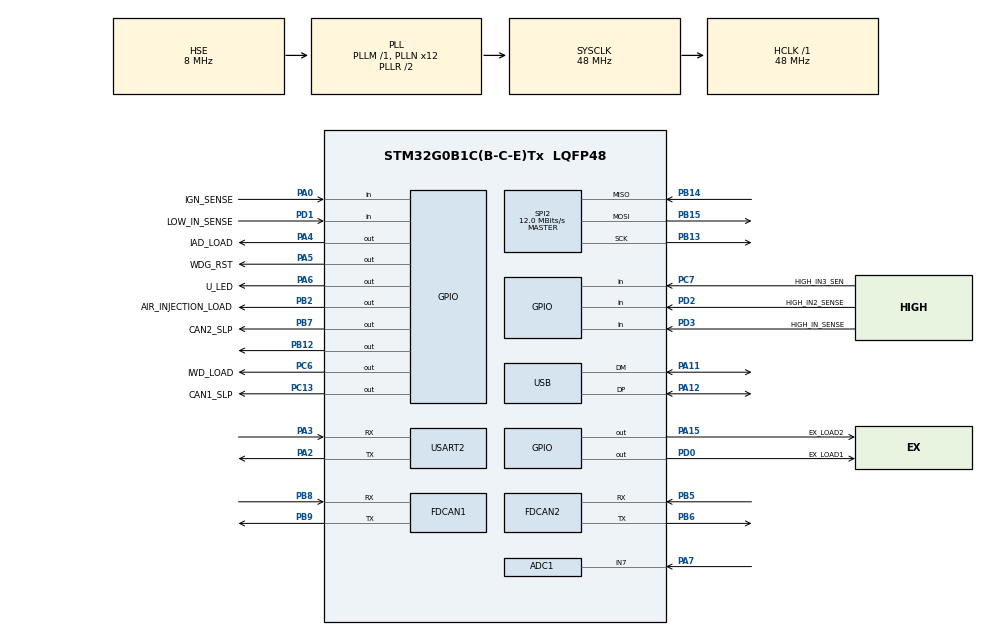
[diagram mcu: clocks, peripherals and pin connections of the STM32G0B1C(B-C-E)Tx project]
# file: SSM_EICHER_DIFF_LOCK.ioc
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ADC1.Channel-0\#ChannelRegularConversion=ADC_CHANNEL_7
ADC1.NbrOfConversionFlag=1
ADC1.Rank-0\#ChannelRegularConversion=1
ADC1.SamplingTime-0\#ChannelRegularConversion=ADC_SAMPLINGTIME_COMMON_1
ADC1.SelectedChannel=ADC_CHANNEL_7
ADC1.master=1
FDCAN1.CalculateBaudRateNominal=1000000
FDCAN1.CalculateTimeQuantumNominal=333.3333333333333
FDCAN2.CalculateBaudRateNominal=250000
FDCAN2.CalculateTimeBitNominal=4000
FDCAN2.CalculateTimeQuantumNominal=250.0
FDCAN2.NominalPrescaler=12
FDCAN2.NominalTimeSeg1=13
FDCAN2.NominalTimeSeg2=2
FREERTOS.Tasks01=defaultTask,24,640,StartDefaultTask,Default,NULL,Dynamic,NULL,NULL
FREERTOS.configTOTAL_HEAP_SIZE=36864
FREERTOS.configUSE_NEWLIB_REENTRANT=1
Mcu.Family=STM32G0
Mcu.Name=STM32G0B1C(B-C-E)Tx
Mcu.Package=LQFP48
NVIC.TIM14_IRQn=true\:3\:0\:false\:false\:true\:false\:false\:true\:true
NVIC.TIM16_FDCAN_IT0_IRQn=true\:3\:0\:false\:false\:true\:true\:true\:true\:true
NVIC.TIM17_FDCAN_IT1_IRQn=true\:3\:0\:false\:false\:true\:true\:true\:true\:true
NVIC.TimeBase=TIM14_IRQn
NVIC.TimeBaseIP=TIM14
NVIC.USART2_LPUART2_IRQn=true\:3\:0\:false\:false\:true\:true\:true\:true\:true
NVIC.USB_UCPD1_2_IRQn=true\:3\:0\:false\:false\:true\:true\:true\:true\:true
PA0.GPIO_Label=IGN_SENSE
PA0.Signal=GPIO_Input
PA11\ [PA9].Mode=Device
PA11\ [PA9].Signal=USB_DM
PA12\ [PA10].Mode=Device
PA12\ [PA10].Signal=USB_DP
PA13.Mode=Serial_Wire
PA13.Signal=SYS_SWDIO
PA14-BOOT0.Mode=Serial_Wire
PA14-BOOT0.Signal=SYS_SWCLK
PA15.GPIO_Label=EX_LOAD2
PA15.Signal=GPIO_Output
PA2.Mode=Asynchronous
PA2.Signal=USART2_TX
PA3.Mode=Asynchronous
PA3.Signal=USART2_RX
PA4.GPIO_Label=IAD_LOAD
PA4.Signal=GPIO_Output
PA5.GPIO_Label=WDG_RST
PA5.Signal=GPIO_Output
PA6.GPIO_Label=U_LED
PA6.Signal=GPIO_Output
PA7.Mode=IN7
PA7.Signal=ADC1_IN7
PB12.Signal=GPIO_Output
PB13.Mode=Full_Duplex_Master
PB13.Signal=SPI2_SCK
PB14.Mode=Full_Duplex_Master
PB14.Signal=SPI2_MISO
PB15.Mode=Full_Duplex_Master
PB15.Signal=SPI2_MOSI
PB2.GPIO_Label=AIR_INJECTION_LOAD
PB2.Signal=GPIO_Output
PB5.Mode=FDCAN_Activate
PB5.Signal=FDCAN2_RX
PB6.Mode=FDCAN_Activate
PB6.Signal=FDCAN2_TX
PB7.GPIO_Label=CAN2_SLP
PB7.Signal=GPIO_Output
PB8.Mode=FDCAN_Activate
PB8.Signal=FDCAN1_RX
PB9.Mode=FDCAN_Activate
PB9.Signal=FDCAN1_TX
PC13.GPIO_Label=CAN1_SLP
PC13.Signal=GPIO_Output
PC14-OSC32_IN\ (PC14).Mode=LSE-External-Oscillator
PC14-OSC32_IN\ (PC14).Signal=RCC_OSC32_IN
PC15-OSC32_OUT\ (PC15).Mode=LSE-External-Oscillator
PC15-OSC32_OUT\ (PC15).Signal=RCC_OSC32_OUT
PC6.GPIO_Label=IWD_LOAD
PC6.Signal=GPIO_Output
PC7.GPIO_Label=HIGH_IN3_SEN
PC7.Signal=GPIO_Input
PD0.GPIO_Label=EX_LOAD1
PD0.Signal=GPIO_Output
PD1.GPIO_Label=LOW_IN_SENSE
PD1.Signal=GPIO_Input
PD2.GPIO_Label=HIGH_IN2_SENSE
PD2.Signal=GPIO_Input
PD3.GPIO_Label=HIGH_IN_SENSE
PD3.Signal=GPIO_Input
PF0-OSC_IN\ (PF0).Mode=HSE-External-Oscillator
PF0-OSC_IN\ (PF0).Signal=RCC_OSC_IN
PF1-OSC_OUT\ (PF1).Mode=HSE-External-Oscillator
PF1-OSC_OUT\ (PF1).Signal=RCC_OSC_OUT
ProjectManager.HeapSize=0x200
ProjectManager.StackSize=0x400
ProjectManager.TargetToolchain=STM32CubeIDE
RCC.ADCFreq_Value=48000000
RCC.AHBFreq_Value=48000000
RCC.CortexFreq_Value=48000000
RCC.EXTERNAL_CLOCK_VALUE=48000
RCC.HCLKFreq_Value=48000000
RCC.HSE_VALUE=8000000
RCC.HSI48_VALUE=48000000
RCC.HSI_VALUE=16000000
RCC.PLLN=12
RCC.PLLSourceVirtual=RCC_PLLSOURCE_HSE
RCC.SYSCLKFreq_VALUE=48000000
RCC.SYSCLKSource=RCC_SYSCLKSOURCE_PLLCLK
RCC.USBFreq_Value=48000000
RCC.VCOOutputFreq_Value=96000000
SPI2.BaudRatePrescaler=SPI_BAUDRATEPRESCALER_4
SPI2.CalculateBaudRate=12.0 MBits/s
SPI2.Direction=SPI_DIRECTION_2LINES
SPI2.Mode=SPI_MODE_MASTER
SPI2.VirtualType=VM_MASTER
TIM16.Period=48000
TIM16.Prescaler=10
USART2.VirtualMode-Asynchronous=VM_ASYNC
USB_DEVICE.CLASS_NAME_FS=CDC
USB_DEVICE.USBD_SELF_POWERED=0
USB_DEVICE.VirtualMode=Cdc
USB_DEVICE.VirtualModeFS=Cdc_FS
VP_FREERTOS_VS_CMSIS_V2.Mode=CMSIS_V2
VP_SYS_VS_DBSignals.Mode=DisableDeadBatterySignals
VP_SYS_VS_tim14.Mode=TIM14
VP_TIM16_VS_ClockSourceINT.Mode=Enable_Timer
VP_USB_DEVICE_VS_USB_DEVICE_CDC_FS.Mode=CDC_FS
board=custom

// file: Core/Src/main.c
/* USER CODE BEGIN Header */
/**
  ******************************************************************************
  * @file           : main.c
  * @brief          : Main program body
  ******************************************************************************
  * @attention
  *
  * Copyright (c) 2025 STMicroelectronics.
  * All rights reserved.
  *
  * This software is licensed under terms that can be found in the LICENSE file
  * in the root directory of this software component.
  * If no LICENSE file comes with this software, it is provided AS-IS.
  *
  ******************************************************************************
  */
/* USER CODE END Header */
#include "main.h"
#include "cmsis_os.h"
#include "usb_device.h"

ADC_HandleTypeDef hadc1;

FDCAN_HandleTypeDef hfdcan1;
FDCAN_HandleTypeDef hfdcan2;

SPI_HandleTypeDef hspi2;

TIM_HandleTypeDef htim16;

UART_HandleTypeDef huart2;

/* Definitions for defaultTask */
osThreadId_t defaultTaskHandle;
const osThreadAttr_t defaultTask_attributes = {
  .name = "defaultTask",
  .priority = (osPriority_t) osPriorityNormal,
  .stack_size = 640 * 4
};
/* USER CODE BEGIN PV */
uint8_t RawByte = 0;
/* USER CODE END PV */

void SystemClock_Config(void);
static void MX_GPIO_Init(void);
static void MX_FDCAN2_Init(void);
static void MX_SPI2_Init(void);
static void MX_TIM16_Init(void);
static void MX_USART2_UART_Init(void);
static void MX_ADC1_Init(void);
//static void MX_FDCAN1_Init(void);
void StartDefaultTask(void *argument);

int main(void)
{

  /* MCU Configuration--------------------------------------------------------*/

  /* Reset of all peripherals, Initializes the Flash interface and the Systick. */
  HAL_Init();

  /* Configure the system clock */
  SystemClock_Config();

  /* Initialize all configured peripherals */
  MX_GPIO_Init();
  MX_FDCAN2_Init();
  MX_SPI2_Init();
  MX_TIM16_Init();
  MX_USART2_UART_Init();
  MX_ADC1_Init();
  MX_FDCAN1_Init();
  /* USER CODE BEGIN 2 */
 // init_logging(&huart2);
  MX_USB_Device_Init();
  /* USER CODE END 2 */

  /* Init scheduler */
  osKernelInitialize();

  /* Create the thread(s) */
  /* creation of defaultTask */
  defaultTaskHandle = osThreadNew(StartDefaultTask, NULL, &defaultTask_attributes);

  /* Start scheduler */
  osKernelStart();

  /* We should never get here as control is now taken by the scheduler */

  /* Infinite loop */
  while (1)
  {

  }
}

void SystemClock_Config(void)
{
  RCC_OscInitTypeDef RCC_OscInitStruct = {0};
  RCC_ClkInitTypeDef RCC_ClkInitStruct = {0};

  /** Configure the main internal regulator output voltage
  */
  HAL_PWREx_ControlVoltageScaling(PWR_REGULATOR_VOLTAGE_SCALE1);

  /** Initializes the RCC Oscillators according to the specified parameters
  * in the RCC_OscInitTypeDef structure.
  */
  RCC_OscInitStruct.OscillatorType = RCC_OSCILLATORTYPE_HSE|RCC_OSCILLATORTYPE_HSI48;
  RCC_OscInitStruct.HSEState = RCC_HSE_ON;
  RCC_OscInitStruct.HSI48State = RCC_HSI48_ON;
  RCC_OscInitStruct.PLL.PLLState = RCC_PLL_ON;
  RCC_OscInitStruct.PLL.PLLSource = RCC_PLLSOURCE_HSE;
  RCC_OscInitStruct.PLL.PLLM = RCC_PLLM_DIV1;
  RCC_OscInitStruct.PLL.PLLN = 12;
  RCC_OscInitStruct.PLL.PLLP = RCC_PLLP_DIV2;
  RCC_OscInitStruct.PLL.PLLQ = RCC_PLLQ_DIV2;
  RCC_OscInitStruct.PLL.PLLR = RCC_PLLR_DIV2;
  if (HAL_RCC_OscConfig(&RCC_OscInitStruct) != HAL_OK)
  {
    Error_Handler();
  }

  /** Initializes the CPU, AHB and APB buses clocks
  */
  RCC_ClkInitStruct.ClockType = RCC_CLOCKTYPE_HCLK|RCC_CLOCKTYPE_SYSCLK
                              |RCC_CLOCKTYPE_PCLK1;
  RCC_ClkInitStruct.SYSCLKSource = RCC_SYSCLKSOURCE_PLLCLK;
  RCC_ClkInitStruct.AHBCLKDivider = RCC_SYSCLK_DIV1;
  RCC_ClkInitStruct.APB1CLKDivider = RCC_HCLK_DIV1;

  if (HAL_RCC_ClockConfig(&RCC_ClkInitStruct, FLASH_LATENCY_1) != HAL_OK)
  {
    Error_Handler();
  }
}

static void MX_ADC1_Init(void)
{

  ADC_ChannelConfTypeDef sConfig = {0};

  /** Configure the global features of the ADC (Clock, Resolution, Data Alignment and number of conversion)
  */
  hadc1.Instance = ADC1;
  hadc1.Init.ClockPrescaler = ADC_CLOCK_SYNC_PCLK_DIV2;
  hadc1.Init.Resolution = ADC_RESOLUTION_12B;
  hadc1.Init.DataAlign = ADC_DATAALIGN_RIGHT;
  hadc1.Init.ScanConvMode = ADC_SCAN_DISABLE;
  hadc1.Init.EOCSelection = ADC_EOC_SINGLE_CONV;
  hadc1.Init.LowPowerAutoWait = DISABLE;
  hadc1.Init.LowPowerAutoPowerOff = DISABLE;
  hadc1.Init.ContinuousConvMode = DISABLE;
  hadc1.Init.NbrOfConversion = 1;
  hadc1.Init.DiscontinuousConvMode = DISABLE;
  hadc1.Init.ExternalTrigConv = ADC_SOFTWARE_START;
  hadc1.Init.ExternalTrigConvEdge = ADC_EXTERNALTRIGCONVEDGE_NONE;
  hadc1.Init.DMAContinuousRequests = DISABLE;
  hadc1.Init.Overrun = ADC_OVR_DATA_PRESERVED;
  hadc1.Init.SamplingTimeCommon1 = ADC_SAMPLETIME_1CYCLE_5;
  hadc1.Init.SamplingTimeCommon2 = ADC_SAMPLETIME_1CYCLE_5;
  hadc1.Init.OversamplingMode = DISABLE;
  hadc1.Init.TriggerFrequencyMode = ADC_TRIGGER_FREQ_HIGH;
  if (HAL_ADC_Init(&hadc1) != HAL_OK)
  {
    Error_Handler();
  }

  /** Configure Regular Channel
  */
  sConfig.Channel = ADC_CHANNEL_7;
  sConfig.Rank = ADC_REGULAR_RANK_1;
  sConfig.SamplingTime = ADC_SAMPLINGTIME_COMMON_1;

  if (HAL_ADC_ConfigChannel(&hadc1, &sConfig) != HAL_OK)
  {
    Error_Handler();
  }

}

void MX_FDCAN1_Init(void)
{

  hfdcan1.Instance = FDCAN1;
  hfdcan1.Init.ClockDivider = FDCAN_CLOCK_DIV1;
  hfdcan1.Init.FrameFormat = FDCAN_FRAME_CLASSIC;
  hfdcan1.Init.Mode = FDCAN_MODE_NORMAL;
  hfdcan1.Init.AutoRetransmission = DISABLE;
  hfdcan1.Init.TransmitPause = DISABLE;
  hfdcan1.Init.ProtocolException = DISABLE;
  hfdcan1.Init.NominalPrescaler = 12;
  hfdcan1.Init.NominalSyncJumpWidth = 1;
  hfdcan1.Init.NominalTimeSeg1 = 13;
  hfdcan1.Init.NominalTimeSeg2 = 2;
  hfdcan1.Init.DataPrescaler = 1;
  hfdcan1.Init.DataSyncJumpWidth = 1;
  hfdcan1.Init.DataTimeSeg1 = 1;
  hfdcan1.Init.DataTimeSeg2 = 1;
  hfdcan1.Init.StdFiltersNbr = 0;
  hfdcan1.Init.ExtFiltersNbr = 0;
  hfdcan1.Init.TxFifoQueueMode = FDCAN_TX_FIFO_OPERATION;
  if (HAL_FDCAN_Init(&hfdcan1) != HAL_OK)
  {
    Error_Handler();
  }

}

void MX_FDCAN2_Init(void)
{

  hfdcan2.Instance = FDCAN2;
  hfdcan2.Init.ClockDivider = FDCAN_CLOCK_DIV1;
  hfdcan2.Init.FrameFormat = FDCAN_FRAME_CLASSIC;
  hfdcan2.Init.Mode = FDCAN_MODE_NORMAL;
  hfdcan2.Init.AutoRetransmission = DISABLE;
  hfdcan2.Init.TransmitPause = DISABLE;
  hfdcan2.Init.ProtocolException = DISABLE;
  hfdcan2.Init.NominalPrescaler = 12;
  hfdcan2.Init.NominalSyncJumpWidth = 1;
  hfdcan2.Init.NominalTimeSeg1 = 13;
  hfdcan2.Init.NominalTimeSeg2 = 2;
  hfdcan2.Init.DataPrescaler = 1;
  hfdcan2.Init.DataSyncJumpWidth = 1;
  hfdcan2.Init.DataTimeSeg1 = 1;
  hfdcan2.Init.DataTimeSeg2 = 1;
  hfdcan2.Init.StdFiltersNbr = 0;
  hfdcan2.Init.ExtFiltersNbr = 0;
  hfdcan2.Init.TxFifoQueueMode = FDCAN_TX_FIFO_OPERATION;
  if (HAL_FDCAN_Init(&hfdcan2) != HAL_OK)
  {
    Error_Handler();
  }

}

static void MX_SPI2_Init(void)
{

  /* SPI2 parameter configuration*/
  hspi2.Instance = SPI2;
  hspi2.Init.Mode = SPI_MODE_MASTER;
  hspi2.Init.Direction = SPI_DIRECTION_2LINES;
  hspi2.Init.DataSize = SPI_DATASIZE_4BIT;
  hspi2.Init.CLKPolarity = SPI_POLARITY_LOW;
  hspi2.Init.CLKPhase = SPI_PHASE_1EDGE;
  hspi2.Init.NSS = SPI_NSS_SOFT;
  hspi2.Init.BaudRatePrescaler = SPI_BAUDRATEPRESCALER_4;
  hspi2.Init.FirstBit = SPI_FIRSTBIT_MSB;
  hspi2.Init.TIMode = SPI_TIMODE_DISABLE;
  hspi2.Init.CRCCalculation = SPI_CRCCALCULATION_DISABLE;
  hspi2.Init.CRCPolynomial = 7;
  hspi2.Init.CRCLength = SPI_CRC_LENGTH_DATASIZE;
  hspi2.Init.NSSPMode = SPI_NSS_PULSE_ENABLE;
  if (HAL_SPI_Init(&hspi2) != HAL_OK)
  {
    Error_Handler();
  }

}

static void MX_TIM16_Init(void)
{

  htim16.Instance = TIM16;
  htim16.Init.Prescaler = 10;
  htim16.Init.CounterMode = TIM_COUNTERMODE_UP;
  htim16.Init.Period = 48000;
  htim16.Init.ClockDivision = TIM_CLOCKDIVISION_DIV1;
  htim16.Init.RepetitionCounter = 0;
  htim16.Init.AutoReloadPreload = TIM_AUTORELOAD_PRELOAD_DISABLE;
  if (HAL_TIM_Base_Init(&htim16) != HAL_OK)
  {
    Error_Handler();
  }

}

static void MX_USART2_UART_Init(void)
{

  huart2.Instance = USART2;
  huart2.Init.BaudRate = 115200;
  huart2.Init.WordLength = UART_WORDLENGTH_8B;
  huart2.Init.StopBits = UART_STOPBITS_1;
  huart2.Init.Parity = UART_PARITY_NONE;
  huart2.Init.Mode = UART_MODE_TX_RX;
  huart2.Init.HwFlowCtl = UART_HWCONTROL_NONE;
  huart2.Init.OverSampling = UART_OVERSAMPLING_16;
  huart2.Init.OneBitSampling = UART_ONE_BIT_SAMPLE_DISABLE;
  huart2.Init.ClockPrescaler = UART_PRESCALER_DIV1;
  huart2.AdvancedInit.AdvFeatureInit = UART_ADVFEATURE_NO_INIT;
  if (HAL_UART_Init(&huart2) != HAL_OK)
  {
    Error_Handler();
  }
  if (HAL_UARTEx_SetTxFifoThreshold(&huart2, UART_TXFIFO_THRESHOLD_1_8) != HAL_OK)
  {
    Error_Handler();
  }
  if (HAL_UARTEx_SetRxFifoThreshold(&huart2, UART_RXFIFO_THRESHOLD_1_8) != HAL_OK)
  {
    Error_Handler();
  }
  if (HAL_UARTEx_DisableFifoMode(&huart2) != HAL_OK)
  {
    Error_Handler();
  }

}

static void MX_GPIO_Init(void)
{
  GPIO_InitTypeDef GPIO_InitStruct = {0};

  /* GPIO Ports Clock Enable */
  __HAL_RCC_GPIOC_CLK_ENABLE();
  __HAL_RCC_GPIOF_CLK_ENABLE();
  __HAL_RCC_GPIOA_CLK_ENABLE();
  __HAL_RCC_GPIOB_CLK_ENABLE();
  __HAL_RCC_GPIOD_CLK_ENABLE();

  /*Configure GPIO pin Output Level */
  HAL_GPIO_WritePin(GPIOC, CAN1_SLP_Pin|IWD_LOAD_Pin, GPIO_PIN_RESET);

  /*Configure GPIO pin Output Level */
  HAL_GPIO_WritePin(GPIOA, IAD_LOAD_Pin|WDG_RST_Pin|U_LED_Pin|EX_LOAD2_Pin, GPIO_PIN_RESET);

  /*Configure GPIO pin Output Level */
  HAL_GPIO_WritePin(GPIOB, AIR_INJECTION_LOAD_Pin|GPIO_PIN_12|CAN2_SLP_Pin, GPIO_PIN_RESET);

  /*Configure GPIO pin Output Level */
  HAL_GPIO_WritePin(EX_LOAD1_GPIO_Port, EX_LOAD1_Pin, GPIO_PIN_RESET);

  /*Configure GPIO pins : CAN1_SLP_Pin IWD_LOAD_Pin */
  GPIO_InitStruct.Pin = CAN1_SLP_Pin|IWD_LOAD_Pin;
  GPIO_InitStruct.Mode = GPIO_MODE_OUTPUT_PP;
  GPIO_InitStruct.Pull = GPIO_NOPULL;
  GPIO_InitStruct.Speed = GPIO_SPEED_FREQ_LOW;
  HAL_GPIO_Init(GPIOC, &GPIO_InitStruct);

  /*Configure GPIO pin : IGN_SENSE_Pin */
  GPIO_InitStruct.Pin = IGN_SENSE_Pin;
  GPIO_InitStruct.Mode = GPIO_MODE_INPUT;
  GPIO_InitStruct.Pull = GPIO_NOPULL;
  HAL_GPIO_Init(IGN_SENSE_GPIO_Port, &GPIO_InitStruct);

  /*Configure GPIO pins : IAD_LOAD_Pin WDG_RST_Pin U_LED_Pin EX_LOAD2_Pin */
  GPIO_InitStruct.Pin = IAD_LOAD_Pin|WDG_RST_Pin|U_LED_Pin|EX_LOAD2_Pin;
  GPIO_InitStruct.Mode = GPIO_MODE_OUTPUT_PP;
  GPIO_InitStruct.Pull = GPIO_NOPULL;
  GPIO_InitStruct.Speed = GPIO_SPEED_FREQ_LOW;
  HAL_GPIO_Init(GPIOA, &GPIO_InitStruct);

  /*Configure GPIO pins : AIR_INJECTION_LOAD_Pin PB12 CAN2_SLP_Pin */
  GPIO_InitStruct.Pin = AIR_INJECTION_LOAD_Pin|GPIO_PIN_12|CAN2_SLP_Pin;
  GPIO_InitStruct.Mode = GPIO_MODE_OUTPUT_PP;
  GPIO_InitStruct.Pull = GPIO_NOPULL;
  GPIO_InitStruct.Speed = GPIO_SPEED_FREQ_LOW;
  HAL_GPIO_Init(GPIOB, &GPIO_InitStruct);

  /*Configure GPIO pin : HIGH_IN3_SEN_Pin */
  GPIO_InitStruct.Pin = HIGH_IN3_SEN_Pin;
  GPIO_InitStruct.Mode = GPIO_MODE_INPUT;
  GPIO_InitStruct.Pull = GPIO_NOPULL;
  HAL_GPIO_Init(HIGH_IN3_SEN_GPIO_Port, &GPIO_InitStruct);

  /*Configure GPIO pin : EX_LOAD1_Pin */
  GPIO_InitStruct.Pin = EX_LOAD1_Pin;
  GPIO_InitStruct.Mode = GPIO_MODE_OUTPUT_PP;
  GPIO_InitStruct.Pull = GPIO_NOPULL;
  GPIO_InitStruct.Speed = GPIO_SPEED_FREQ_LOW;
  HAL_GPIO_Init(EX_LOAD1_GPIO_Port, &GPIO_InitStruct);

  /*Configure GPIO pins : LOW_IN_SENSE_Pin HIGH_IN2_SENSE_Pin HIGH_IN_SENSE_Pin */
  GPIO_InitStruct.Pin = LOW_IN_SENSE_Pin|HIGH_IN2_SENSE_Pin|HIGH_IN_SENSE_Pin;
  GPIO_InitStruct.Mode = GPIO_MODE_INPUT;
  GPIO_InitStruct.Pull = GPIO_NOPULL;
  HAL_GPIO_Init(GPIOD, &GPIO_InitStruct);

}

/* USER CODE BEGIN 4 */
//void HAL_UART_RxCpltCallback(UART_HandleTypeDef *huart)
//{
//
//    if (huart->Instance == USART2)
//    {
//    	card_buff_rx_data(RawByte);
//        HAL_UART_Receive_IT(&huart2, (uint8_t *)&RawByte, 1);
//    	//HAL_UART_Receive_DMA(&huart1, (uint8_t *)&GsmRawByte, 1);
//    }
//
//}

/* USER CODE END 4 */

void HAL_TIM_PeriodElapsedCallback(TIM_HandleTypeDef *htim)
{
  if (htim->Instance == TIM14) {
    HAL_IncTick();
  }
}

void Error_Handler(void)
{
  __disable_irq();
  while (1)
  {
  }
}
